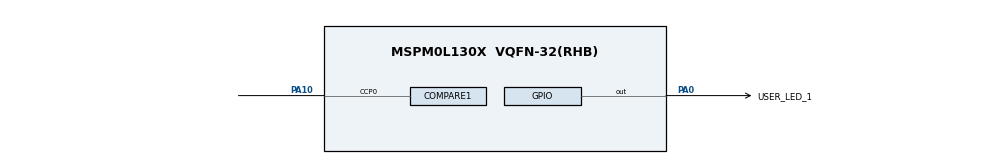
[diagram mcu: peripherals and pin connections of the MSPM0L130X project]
// @cliArgs --device "MSPM0L130X" --package "VQFN-32(RHB)" --part "Default"
// @cliArgs --board /ti/boards/LP_MSPM0L1306 --rtos nortos

/**
 * Import the modules used in this configuration.
 */
const Board = scripting.addModule("/ti/driverlib/Board", {}, false);
const SYSCTL = scripting.addModule("/ti/driverlib/SYSCTL", {}, false);
const COMPARE  = scripting.addModule("/ti/driverlib/COMPARE", {}, false);
const COMPARE1 = COMPARE.addInstance();
const GPIO     = scripting.addModule("/ti/driverlib/GPIO", {}, false);
const GPIO1    = GPIO.addInstance();

/**
 * Write custom configuration values to the imported modules.
 */
COMPARE1.$name                      = "COMPARE_0";
COMPARE1.timerPeriod                = 5;
COMPARE1.interrupts                 = ["LOAD"];
COMPARE1.peripheral.$assign         = "TIMG4";
COMPARE1.peripheral.ccp0Pin.$assign = "PA10";


GPIO1.$name                         = "GPIO_LEDS";
GPIO1.associatedPins[0].$name       = "USER_LED_1";
GPIO1.associatedPins[0].initialValue        = "SET";
GPIO1.associatedPins[0].pin.$assign = "PA0";

SYSCTL.clockTreeEn = true;
